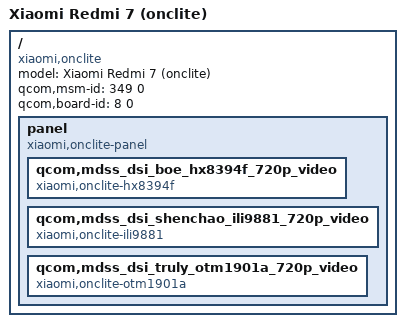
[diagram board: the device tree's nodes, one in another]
/dts-v1/;

/include/ "msm8953.dtsi"

/ {
	model = "Xiaomi Redmi 7 (onclite)";
	compatible = "xiaomi,onclite", "qcom,sdm632", "lk2nd,device";
	qcom,msm-id = <349 0>;
	qcom,board-id = <8 0>;

	panel {
		compatible = "xiaomi,onclite-panel";

		qcom,mdss_dsi_boe_hx8394f_720p_video {
			compatible = "xiaomi,onclite-hx8394f";
		};
		qcom,mdss_dsi_shenchao_ili9881_720p_video {
			compatible = "xiaomi,onclite-ili9881";
		};
		qcom,mdss_dsi_truly_otm1901a_720p_video {
			compatible = "xiaomi,onclite-otm1901a";
		};
	};

	__symbols__ {};
};
